# VTM_VTM_CFG2_00B01000h register map
Vendor: Texas Instruments
Peripheral module from a debugger description file (folder AM275x).
Registers are 32-bit, read-write, reset 0x0 unless marked. A register's access mark holds for its fields unless they carry their own. Offsets are as the file gives them; lines under a group give offsets from that group; [hi:lo] are bit positions; {n}, {i} and the like mark numbered series; 'fields as' and 'values as' point back to an identical list; <NAME> marks a mode.

## VTM_CFG2
0x0C VTM_CFG2_MISC_CTRL — VTM miscellaneous control bits.
  [0] ANY_MAXT_OUTRG_ALERT_EN — This bit when enabled will cause the VTM's output therm_maxtemp_outrange_alert to be driven high, if any of the sources for the maxt_outrg_alert, is set high. Whenever all the maxt_outrg_alert enabled sensor alerts, out of the 8 possible are back to 0 then the output, therm_maxtemp_outrange_alert, will also return to 0. Reset is at POR only. Reset Source: mod_por_rst_n
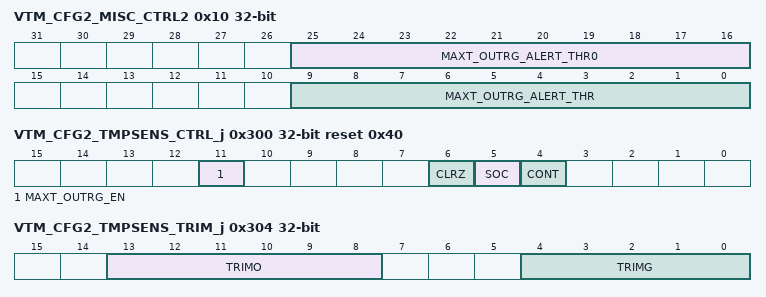
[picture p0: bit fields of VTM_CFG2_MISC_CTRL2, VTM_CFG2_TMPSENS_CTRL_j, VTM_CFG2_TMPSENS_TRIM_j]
0x10 VTM_CFG2_MISC_CTRL2 — VTM miscellaneous control bits.
  [25:16] MAXT_OUTRG_ALERT_THR0 — This defines the global max temperature out of range safe sample value. If the alert is enabled globally and for the sensor and the sensor reads a value <= this value then the alert is cleared after being triggered. This safe threshold defines at what temp the alert can be cleared. Reset is at POR only. Reset Source: mod_por_rst_n
  [9:0] MAXT_OUTRG_ALERT_THR — This defines the global max temperature out of range sample value. If the alert is enabled globally and for the sensor and the sensor reads a value >= this value then the alert is triggered. Reset is at POR only. Reset Source: mod_por_rst_n
0x300 VTM_CFG2_TMPSENS_CTRL_j reset 0x40 — Temperature Sensor Band-gap control register for sensor j.
  [11] MAXT_OUTRG_EN — Enable out-of-range event. This bit enables generation of the alert in case the given temperature sensors generates a temp code above a programmed max. 0 = Don't generate alert. 1 = Generate alert. Reset value is POR only. Reset Source: mod_por_rst_n
  [6] CLRZ — Temp-Monitor control: 0 = Reset all Temp-monitor digital outputs. 1 = Allow operation of sensor. Reset value is POR only. Reset Source: mod_por_rst_n
  [5] SOC — Temp-Monitor control: ADC Start of Conversion. A transition from 0 to 1 starts a new ADC conversion cycle. The bit with automatically clear when the conversion has completed. This mode is not valid when already in continuous mode. Reset value is POR only. Reset Source: mod_por_rst_n
  [4] CONT — Temp-Monitor control: ADC Continuous mode. Setting this mode enables the VTM to continuously monitor the sensor automatically. Each sample period the sensor will be accessed and the results captured. Reset value is POR only. Reset Source: mod_por_rst_n
0x304 VTM_CFG2_TMPSENS_TRIM_j — Temperature Sensor Band-gap trim values register for sensor j. The default reset values will not be necessarily overwritten. The write capability in the MMR is for having the option to debug and have software driven adjustments if necessary.
  [13:8] TRIMO — Trim offset bits in the temp sensor. Reset value is from e-fuse at POR, efuse_tmpsens[j]_trimo. Reset Source: mod_por_rst_n
  [4:0] TRIMG — Trim gain bits in the temp sensor. Reset value is from e-fuse at POR, efuse_tmpsens[j]_trimg. Reset Source: mod_por_rst_n
